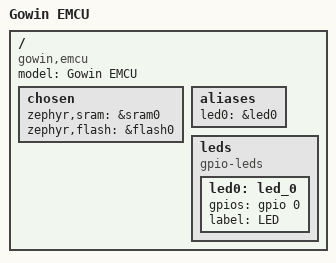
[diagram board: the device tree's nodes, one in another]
/*
 * Copyright (c) 2023 YuLong Yao <feilongphone@gmail.com>
 *
 * SPDX-License-Identifier: Apache-2.0
 */

/dts-v1/;
#include <gowin/empu/gwempu.dtsi>

/ {
	model = "Gowin EMCU";
	compatible = "gowin,emcu";

	chosen {
		// zephyr,console = &uart0;
		// zephyr,shell-uart = &uart0;
		zephyr,sram = &sram0;
		zephyr,flash = &flash0;
	};

	aliases {
		led0 = &led0;
	};

	leds {
		compatible = "gpio-leds";
		led0: led_0 {
			gpios = <&gpio 0 0>;
			label = "LED";
		};
	};

};

// &uart0 {
	//         compatible = "nordic,nrf-uart";
	//         current-speed = <115200>;
	//         status = "okay";
	//         pinctrl-0 = <&uart0_default>;
	//         pinctrl-1 = <&uart0_sleep>;
	//         pinctrl-names = "default", "sleep";
// };
